# ATmega1284P device description
Architecture: AVR8; Family: megaAVR
Registers are 8-bit, access not given, no defined reset value unless marked. A register's access mark holds for its fields unless they carry their own. Offsets are from the block's base; [hi:lo] are bit positions; {n}, {i} and the like mark numbered series.

## JTAG — JTAG Interface
Instances: JTAG 0x00
0x51 OCDR — On-Chip Debug Related Register in I/O Memory
0x54 MCUSR — MCU Status Register
  [4] JTRF — JTAG Reset Flag
0x55 MCUCR — MCU Control Register
  [7] JTD — JTAG Interface Disable

## EEPROM
Instances: EEPROM 0x00
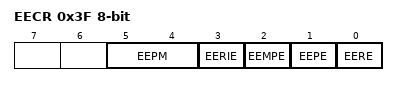
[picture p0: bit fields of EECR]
0x3F EECR — EEPROM Control Register
  [5:4] EEPM — EEPROM Programming Mode Bits
    0=Erase and Write in one operation; 1=Erase Only; 2=Write Only
  [3] EERIE — EEPROM Ready Interrupt Enable
  [2] EEMPE — EEPROM Master Write Enable
  [1] EEPE — EEPROM Write Enable
  [0] EERE — EEPROM Read Enable
0x40 EEDR — EEPROM Data Register
  [7:0] EEDR — EEPROM Data bits
0x41 EEAR 16-bit — EEPROM Address Register Low Bytes
  [11:0] EEAR — EEPROM Address bits

## TWI — Two Wire Serial Interface
Instances: TWI 0x00
0xB8 TWBR — TWI Bit Rate register
  [7:0] TWBR — TWI Bit Rate bits
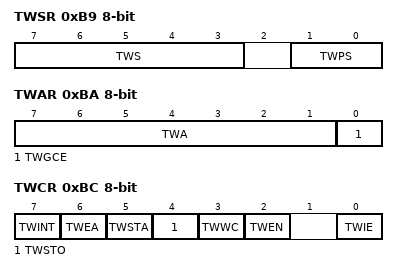
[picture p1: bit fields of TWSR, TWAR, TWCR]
0xB9 TWSR — TWI Status Register
  [7:3] TWS (bit 3 of the value upward) — TWI Status
  [1:0] TWPS — TWI Prescaler
    0=1; 1=4; 2=16; 3=64
0xBA TWAR — TWI (Slave) Address register
  [7:1] TWA — TWI (Slave) Address register Bits
  [0] TWGCE — TWI General Call Recognition Enable Bit
0xBB TWDR — TWI Data register
  [7:0] TWD — TWI Data bits
0xBC TWCR — TWI Control Register
  [7] TWINT — TWI Interrupt Flag
  [6] TWEA — TWI Enable Acknowledge Bit
  [5] TWSTA — TWI Start Condition Bit
  [4] TWSTO — TWI Stop Condition Bit
  [3] TWWC — TWI Write Collition Flag
  [2] TWEN — TWI Enable Bit
  [0] TWIE — TWI Interrupt Enable
0xBD TWAMR — TWI (Slave) Address Mask Register
  [7:1] TWAM

## SPI — Serial Peripheral Interface
Instances: SPI 0x00
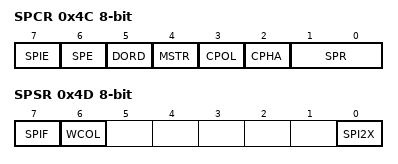
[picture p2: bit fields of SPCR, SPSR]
0x4C SPCR — SPI Control Register
  [7] SPIE — SPI Interrupt Enable
  [6] SPE — SPI Enable
  [5] DORD — Data Order
  [4] MSTR — Master/Slave Select
  [3] CPOL — Clock polarity
  [2] CPHA — Clock Phase
  [1:0] SPR — SPI Clock Rate Selects
    0=fosc/4; 1=fosc/16; 2=fosc/64; 3=fosc/128; 4=fosc/2; 5=fosc/8; 6=fosc/32; 7=fosc/64
0x4D SPSR — SPI Status Register
  [7] SPIF — SPI Interrupt Flag
  [6] WCOL — Write Collision Flag
  [0] SPI2X — Double SPI Speed Bit
0x4E SPDR — SPI Data Register
  [7:0] SPD — SPI Data bits

## WDT — Watchdog Timer
Instances: WDT 0x00
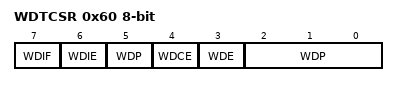
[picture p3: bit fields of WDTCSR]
0x60 WDTCSR — Watchdog Timer Control Register
  [7] WDIF — Watchdog Timeout Interrupt Flag
  [6] WDIE — Watchdog Timeout Interrupt Enable
  [4] WDCE — Watchdog Change Enable
  [3] WDE — Watch Dog Enable
  [5,2:0] WDP — Watchdog Timer Prescaler Bits
    0=Oscillator Cycles 2K; 1=Oscillator Cycles 4K; 2=Oscillator Cycles 8K; 3=Oscillator Cycles 16K; 4=Oscillator Cycles 32K; 5=Oscillator Cycles 64K; 6=Oscillator Cycles 128K; 7=Oscillator Cycles 256K; 8=Oscillator Cycles 512K; 9=Oscillator Cycles 1024K

## CPU — CPU Registers
Instances: CPU 0x00
Parameters: CORE_VERSION=V2E
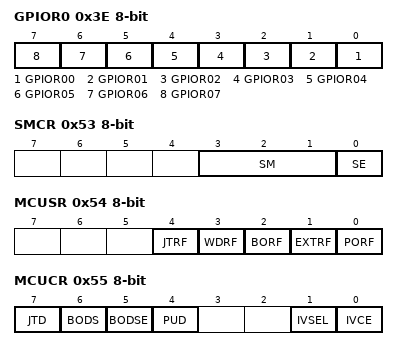
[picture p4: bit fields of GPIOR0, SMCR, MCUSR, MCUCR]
0x3E GPIOR0 — General Purpose IO Register 0
  [n] GPIOR{n:02} (n=0..7) — General Purpose IO Register 0 bit {n}
0x4A GPIOR1 — General Purpose IO Register 1
  [7:0] GPIOR (bit 10 of the value upward) — General Purpose IO Register 1 bis
0x4B GPIOR2 — General Purpose IO Register 2
  [7:0] GPIOR (bit 20 of the value upward) — General Purpose IO Register 2 bis
0x53 SMCR — Sleep Mode Control Register
  [3:1] SM — Sleep Mode Select bits
    0=IDLE; 1=ADC (ADC Noise Reduction (If Available)); 2=PDOWN (Power Down); 3=PSAVE (Power Save); 6=STDBY (Standby); 7=ESTDBY (Extended Standby)
  [0] SE — Sleep Enable
0x54 MCUSR — MCU Status Register
  [4] JTRF — JTAG Reset Flag
  [3] WDRF — Watchdog Reset Flag
  [2] BORF — Brown-out Reset Flag
  [1] EXTRF — External Reset Flag
  [0] PORF — Power-on reset flag
0x55 MCUCR — MCU Control Register
  [7] JTD — JTAG Interface Disable
  [6] BODS — BOD Power Down in Sleep
  [5] BODSE — BOD Power Down in Sleep Enable
  [4] PUD — Pull-up disable
  [1] IVSEL — Interrupt Vector Select
  [0] IVCE — Interrupt Vector Change Enable
0x5B RAMPZ bits used 0 — RAM Page Z Select Register
0x5D SP 16-bit — Stack Pointer
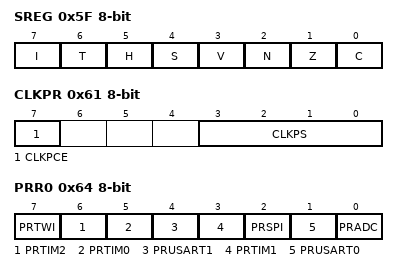
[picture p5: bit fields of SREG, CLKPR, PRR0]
0x5F SREG — Status Register
  [7] I — Global Interrupt Enable
  [6] T — Bit Copy Storage
  [5] H — Half Carry Flag
  [4] S — Sign Bit
  [3] V — Two's Complement Overflow Flag
  [2] N — Negative Flag
  [1] Z — Zero Flag
  [0] C — Carry Flag
0x61 CLKPR
  [7] CLKPCE
  [3:0] CLKPS
    0=1; 1=2; 2=4; 3=8; 4=16; 5=32; 6=64; 7=128; 8=256
0x64 PRR0 — Power Reduction Register0
  [7] PRTWI — Power Reduction TWI
  [6] PRTIM2 — Power Reduction Timer/Counter2
  [5] PRTIM0 — Power Reduction Timer/Counter0
  [4] PRUSART1 — Power Reduction USART1
  [3] PRTIM1 — Power Reduction Timer/Counter1
  [2] PRSPI — Power Reduction Serial Peripheral Interface
  [1] PRUSART0 — Power Reduction USART0
  [0] PRADC — Power Reduction ADC
0x65 PRR1 — Power Reduction Register1
  [0] PRTIM3 — Power Reduction Timer/Counter3
0x66 OSCCAL — Oscillator Calibration Value
  [7:0] OSCCAL — Oscillator Calibration
Value list OSCCAL_VALUE_ADDRESSES: 0=8_0_MHz
